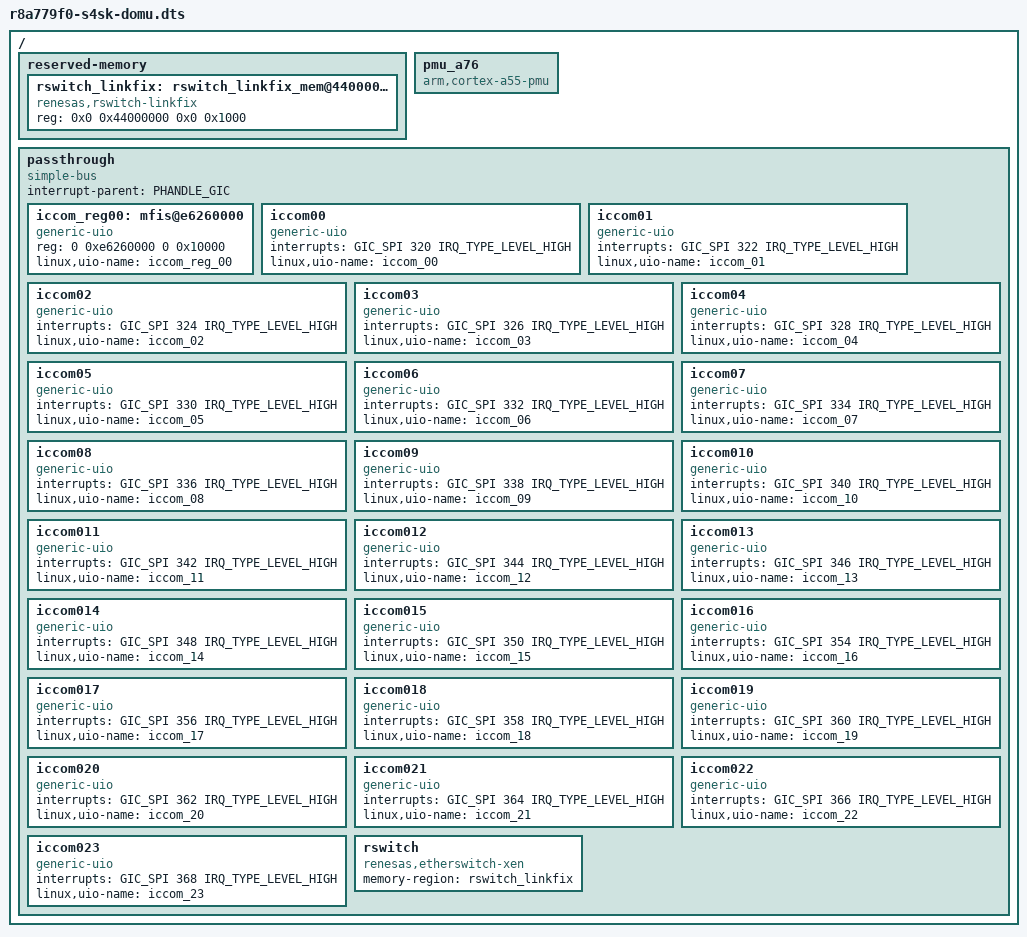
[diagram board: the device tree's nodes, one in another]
/dts-v1/;

#include <dt-bindings/interrupt-controller/arm-gic.h>

/*
 * The device tree compiler (DTC) is allocating the phandle from 1 to
 * onwards. Reserve a high value for the GIC phandle.
 */
#define PHANDLE_GIC (65000)

/ {
	#address-cells = <2>;
	#size-cells = <2>;

	reserved-memory {
		#address-cells = <2>;
		#size-cells = <2>;
		ranges;

		/* R-Switch LINKFIX table */
		rswitch_linkfix: rswitch_linkfix_mem@44000000 {
			compatible = "renesas,rswitch-linkfix";
			reg = <0x0 0x44000000 0x0 0x1000>;
		};
	};

	/*
	 * Just add compatible string without interrupts-extended
	 * node as it can not be shared by Xen.
	 */
	pmu_a76 {
		compatible = "arm,cortex-a55-pmu";
	};

	passthrough {
		compatible = "simple-bus";
		ranges;

		#address-cells = <2>;
		#size-cells = <2>;

		/* This must point to Xen interrupt-parent. */
		interrupt-parent = <PHANDLE_GIC>;

		iccom_reg00: mfis@e6260000 {
			compatible = "generic-uio";
			reg = <0 0xe6260000 0 0x10000>;
			linux,uio-name = "iccom_reg_00";
		};

		iccom00 {
			compatible = "generic-uio";
			interrupts = <GIC_SPI 320 IRQ_TYPE_LEVEL_HIGH>;
			linux,uio-name = "iccom_00";
		};

		iccom01 {
			compatible = "generic-uio";
			interrupts = <GIC_SPI 322 IRQ_TYPE_LEVEL_HIGH>;
			linux,uio-name = "iccom_01";
		};

		iccom02 {
			compatible = "generic-uio";
			interrupts = <GIC_SPI 324 IRQ_TYPE_LEVEL_HIGH>;
			linux,uio-name = "iccom_02";
		};

		iccom03 {
			compatible = "generic-uio";
			interrupts = <GIC_SPI 326 IRQ_TYPE_LEVEL_HIGH>;
			linux,uio-name = "iccom_03";
		};

		iccom04 {
			compatible = "generic-uio";
			interrupts = <GIC_SPI 328 IRQ_TYPE_LEVEL_HIGH>;
			linux,uio-name = "iccom_04";
		};

		iccom05 {
			compatible = "generic-uio";
			interrupts = <GIC_SPI 330 IRQ_TYPE_LEVEL_HIGH>;
			linux,uio-name = "iccom_05";
		};

		iccom06 {
			compatible = "generic-uio";
			interrupts = <GIC_SPI 332 IRQ_TYPE_LEVEL_HIGH>;
			linux,uio-name = "iccom_06";
		};

		iccom07 {
			compatible = "generic-uio";
			interrupts = <GIC_SPI 334 IRQ_TYPE_LEVEL_HIGH>;
			linux,uio-name = "iccom_07";
		};

		iccom08 {
			compatible = "generic-uio";
			interrupts = <GIC_SPI 336 IRQ_TYPE_LEVEL_HIGH>;
			linux,uio-name = "iccom_08";
		};

		iccom09 {
			compatible = "generic-uio";
			interrupts = <GIC_SPI 338 IRQ_TYPE_LEVEL_HIGH>;
			linux,uio-name = "iccom_09";
		};

		iccom010 {
			compatible = "generic-uio";
			interrupts = <GIC_SPI 340 IRQ_TYPE_LEVEL_HIGH>;
			linux,uio-name = "iccom_10";
		};


		iccom011 {
			compatible = "generic-uio";
			interrupts = <GIC_SPI 342 IRQ_TYPE_LEVEL_HIGH>;
			linux,uio-name = "iccom_11";
		};

		iccom012 {
			compatible = "generic-uio";
			interrupts = <GIC_SPI 344 IRQ_TYPE_LEVEL_HIGH>;
			linux,uio-name = "iccom_12";
		};

		iccom013 {
			compatible = "generic-uio";
			interrupts = <GIC_SPI 346 IRQ_TYPE_LEVEL_HIGH>;
			linux,uio-name = "iccom_13";
		};

		iccom014 {
			compatible = "generic-uio";
			interrupts = <GIC_SPI 348 IRQ_TYPE_LEVEL_HIGH>;
			linux,uio-name = "iccom_14";
		};

		iccom015 {
			compatible = "generic-uio";
			interrupts = <GIC_SPI 350 IRQ_TYPE_LEVEL_HIGH>;
			linux,uio-name = "iccom_15";
		};
		iccom016 {
			compatible = "generic-uio";
			interrupts = <GIC_SPI 354 IRQ_TYPE_LEVEL_HIGH>;
			linux,uio-name = "iccom_16";
		};

		iccom017 {
			compatible = "generic-uio";
			interrupts = <GIC_SPI 356 IRQ_TYPE_LEVEL_HIGH>;
			linux,uio-name = "iccom_17";
		};

		iccom018 {
			compatible = "generic-uio";
			interrupts = <GIC_SPI 358 IRQ_TYPE_LEVEL_HIGH>;
			linux,uio-name = "iccom_18";
		};

		iccom019 {
			compatible = "generic-uio";
			interrupts = <GIC_SPI 360 IRQ_TYPE_LEVEL_HIGH>;
			linux,uio-name = "iccom_19";
		};

		iccom020 {
			compatible = "generic-uio";
			interrupts = <GIC_SPI 362 IRQ_TYPE_LEVEL_HIGH>;
			linux,uio-name = "iccom_20";
		};

		iccom021 {
			compatible = "generic-uio";
			interrupts = <GIC_SPI 364 IRQ_TYPE_LEVEL_HIGH>;
			linux,uio-name = "iccom_21";
		};

		iccom022 {
			compatible = "generic-uio";
			interrupts = <GIC_SPI 366 IRQ_TYPE_LEVEL_HIGH>;
			linux,uio-name = "iccom_22";
		};

		iccom023 {
			compatible = "generic-uio";
			interrupts = <GIC_SPI 368 IRQ_TYPE_LEVEL_HIGH>;
			linux,uio-name = "iccom_23";
		};

		rswitch {
			compatible = "renesas,etherswitch-xen";
			memory-region = <&rswitch_linkfix>;
		};
	};
};
